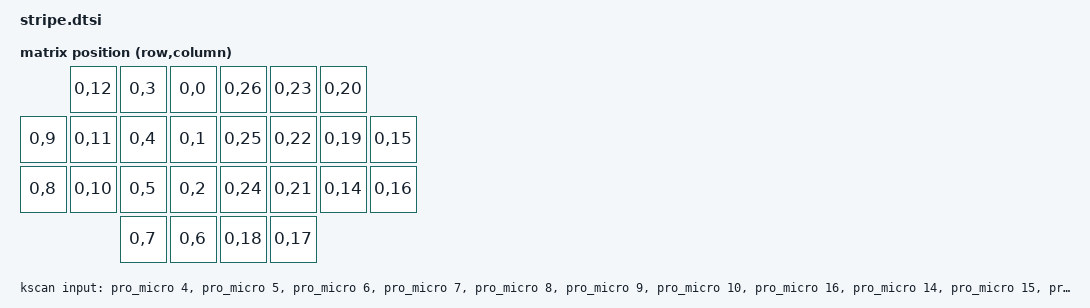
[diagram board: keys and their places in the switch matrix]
// This file was generated from a template. Edit it to match your keyboard.
// See https://zmk.dev/docs/development/hardware-integration/new-shield for more
// instructions.

#include <dt-bindings/zmk/matrix_transform.h>

#include "stripe-layouts.dtsi"

/ {
    chosen {
        zmk,physical-layout = &default_layout;
    };

    kscan: kscan {
        compatible = "zmk,kscan-gpio-direct";
        wakeup-source;

        input-gpios
            = <&pro_micro 4  (GPIO_ACTIVE_LOW | GPIO_PULL_UP)>
            , <&pro_micro 5  (GPIO_ACTIVE_LOW | GPIO_PULL_UP)>
            , <&pro_micro 6  (GPIO_ACTIVE_LOW | GPIO_PULL_UP)>
            , <&pro_micro 7  (GPIO_ACTIVE_LOW | GPIO_PULL_UP)>
            , <&pro_micro 8  (GPIO_ACTIVE_LOW | GPIO_PULL_UP)>
            , <&pro_micro 9  (GPIO_ACTIVE_LOW | GPIO_PULL_UP)>
            , <&pro_micro 10 (GPIO_ACTIVE_LOW | GPIO_PULL_UP)>
            , <&pro_micro 16 (GPIO_ACTIVE_LOW | GPIO_PULL_UP)>
            , <&pro_micro 14 (GPIO_ACTIVE_LOW | GPIO_PULL_UP)>
            , <&pro_micro 15 (GPIO_ACTIVE_LOW | GPIO_PULL_UP)>
            , <&pro_micro 18 (GPIO_ACTIVE_LOW | GPIO_PULL_UP)>
            , <&pro_micro 19 (GPIO_ACTIVE_LOW | GPIO_PULL_UP)>
            , <&pro_micro 20 (GPIO_ACTIVE_LOW | GPIO_PULL_UP)>
            , <&pro_micro 21 (GPIO_ACTIVE_LOW | GPIO_PULL_UP)>
            ;
    };

    default_transform: default_transform {
        // See https://zmk.dev/docs/development/hardware-integration/new-shield#matrix-transform
        // for how to configure this
        compatible = "zmk,matrix-transform";
        columns = <26>;
        rows = <1>;

        map = <
                      RC(0, 12) RC(0, 3) RC(0, 0)   RC(0, 26) RC(0, 23) RC(0, 20)                             
            RC(0, 9)  RC(0, 11) RC(0, 4) RC(0, 1)   RC(0, 25) RC(0, 22) RC(0, 19) RC(0, 15)
            RC(0, 8)  RC(0, 10) RC(0, 5) RC(0, 2)   RC(0, 24) RC(0, 21) RC(0, 14) RC(0, 16)
                                RC(0, 7) RC(0, 6)   RC(0, 18) RC(0, 17)
        >;
    };
};
